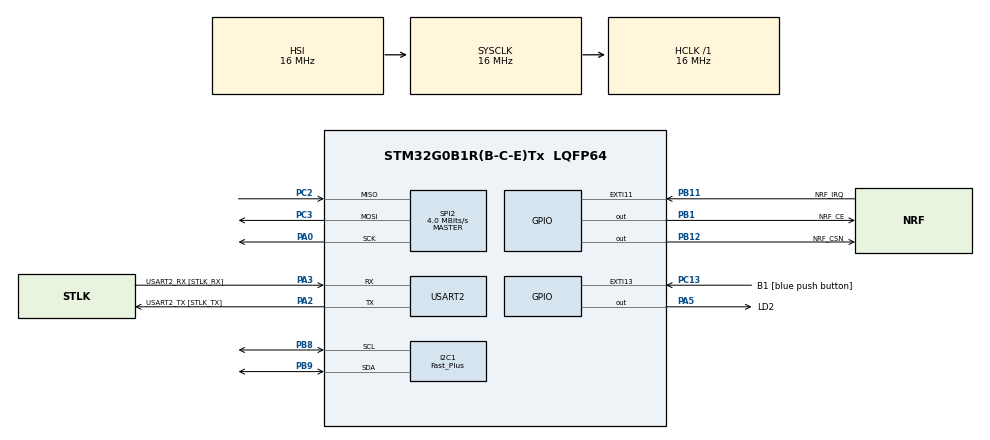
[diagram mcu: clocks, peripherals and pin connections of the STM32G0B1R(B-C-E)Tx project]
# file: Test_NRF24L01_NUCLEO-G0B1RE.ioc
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I2C1.I2C_Speed_Mode=I2C_Fast_Plus
I2C1.Timing=0x00200105
Mcu.Family=STM32G0
Mcu.Name=STM32G0B1R(B-C-E)Tx
Mcu.Package=LQFP64
PA0.Mode=Full_Duplex_Master
PA0.Signal=SPI2_SCK
PA13.GPIO_Label=TMS
PA13.Mode=Serial_Wire
PA13.Signal=SYS_SWDIO
PA14-BOOT0.GPIO_Label=TCK
PA14-BOOT0.Mode=Serial_Wire
PA14-BOOT0.Signal=SYS_SWCLK
PA2.GPIO_Label=USART2_TX [STLK_TX]
PA2.Mode=Asynchronous
PA2.Signal=USART2_TX
PA3.GPIO_Label=USART2_RX [STLK_RX]
PA3.Mode=Asynchronous
PA3.Signal=USART2_RX
PA5.GPIO_Label=LD2
PA5.GPIO_Speed=GPIO_SPEED_FREQ_HIGH
PA5.Signal=GPIO_Output
PB1.GPIO_Label=NRF_CE
PB1.Signal=GPIO_Output
PB11.GPIO_Label=NRF_IRQ
PB11.Signal=GPXTI11
PB12.GPIO_Label=NRF_CSN
PB12.Signal=GPIO_Output
PB8.Mode=I2C
PB8.Signal=I2C1_SCL
PB9.Mode=I2C
PB9.Signal=I2C1_SDA
PC13.GPIO_Label=B1 [blue push button]
PC13.Signal=GPXTI13
PC14-OSC32_IN\ (PC14).Mode=LSE-External-Oscillator
PC14-OSC32_IN\ (PC14).Signal=RCC_OSC32_IN
PC15-OSC32_OUT\ (PC15).Mode=LSE-External-Oscillator
PC15-OSC32_OUT\ (PC15).Signal=RCC_OSC32_OUT
PC2.Mode=Full_Duplex_Master
PC2.Signal=SPI2_MISO
PC3.Mode=Full_Duplex_Master
PC3.Signal=SPI2_MOSI
PF0-OSC_IN\ (PF0).GPIO_Label=MCO
PF0-OSC_IN\ (PF0).Mode=HSE-External-Clock-Source
PF0-OSC_IN\ (PF0).Signal=RCC_OSC_IN
ProjectManager.HeapSize=0x200
ProjectManager.StackSize=0x400
ProjectManager.TargetToolchain=STM32CubeIDE
RCC.AHBFreq_Value=16000000
RCC.CortexFreq_Value=16000000
RCC.EXTERNAL_CLOCK_VALUE=12288000
RCC.HCLKFreq_Value=16000000
RCC.HSE_VALUE=8000000
RCC.HSI48_VALUE=48000000
RCC.HSI_VALUE=16000000
RCC.SYSCLKFreq_VALUE=16000000
RCC.USBFreq_Value=48000000
RCC.VCOOutputFreq_Value=128000000
SPI2.BaudRatePrescaler=SPI_BAUDRATEPRESCALER_4
SPI2.CalculateBaudRate=4.0 MBits/s
SPI2.DataSize=SPI_DATASIZE_8BIT
SPI2.Direction=SPI_DIRECTION_2LINES
SPI2.Mode=SPI_MODE_MASTER
SPI2.NSSPMode=SPI_NSS_PULSE_DISABLE
SPI2.VirtualType=VM_MASTER
USART2.VirtualMode-Asynchronous=VM_ASYNC
VP_SYS_VS_DBSignals.Mode=DisableDeadBatterySignals
board=NUCLEO-G0B1RE

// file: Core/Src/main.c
/* USER CODE BEGIN Header */
/**
  ******************************************************************************
  * @file           : main.c
  * @brief          : Main program body
  ******************************************************************************
  * @attention
  *
  * Copyright (c) 2025 STMicroelectronics.
  * All rights reserved.
  *
  * This software is licensed under terms that can be found in the LICENSE file
  * in the root directory of this software component.
  * If no LICENSE file comes with this software, it is provided AS-IS.
  *
  ******************************************************************************
  */
/* USER CODE END Header */
#include "main.h"

/* USER CODE BEGIN Includes */
#include "radio.h"
#include "nrf24.h"
#include "ssd1306.h"
#include "fonts.h"
#include "test_screen.h"

/* USER CODE END Includes */

I2C_HandleTypeDef hi2c1;

SPI_HandleTypeDef hspi2;

UART_HandleTypeDef huart2;

void SystemClock_Config(void);
static void MX_GPIO_Init(void);
static void MX_USART2_UART_Init(void);
static void MX_SPI2_Init(void);
static void MX_I2C1_Init(void);

int main(void)
{

  /* MCU Configuration--------------------------------------------------------*/

  /* Reset of all peripherals, Initializes the Flash interface and the Systick. */
  HAL_Init();

  /* Configure the system clock */
  SystemClock_Config();

  /* Initialize all configured peripherals */
  MX_GPIO_Init();
  MX_USART2_UART_Init();
  MX_SPI2_Init();
  MX_I2C1_Init();
  /* USER CODE BEGIN 2 */

  // runTestScreen();
  runRadio();
  // runTestScreen();
  /* USER CODE END 2 */

  /* Infinite loop */
  while (1)
  {

  }
}

void SystemClock_Config(void)
{
  RCC_OscInitTypeDef RCC_OscInitStruct = {0};
  RCC_ClkInitTypeDef RCC_ClkInitStruct = {0};

  /** Configure the main internal regulator output voltage
  */
  HAL_PWREx_ControlVoltageScaling(PWR_REGULATOR_VOLTAGE_SCALE1);

  /** Initializes the RCC Oscillators according to the specified parameters
  * in the RCC_OscInitTypeDef structure.
  */
  RCC_OscInitStruct.OscillatorType = RCC_OSCILLATORTYPE_HSI;
  RCC_OscInitStruct.HSIState = RCC_HSI_ON;
  RCC_OscInitStruct.HSIDiv = RCC_HSI_DIV1;
  RCC_OscInitStruct.HSICalibrationValue = RCC_HSICALIBRATION_DEFAULT;
  RCC_OscInitStruct.PLL.PLLState = RCC_PLL_NONE;
  if (HAL_RCC_OscConfig(&RCC_OscInitStruct) != HAL_OK)
  {
    Error_Handler();
  }

  /** Initializes the CPU, AHB and APB buses clocks
  */
  RCC_ClkInitStruct.ClockType = RCC_CLOCKTYPE_HCLK|RCC_CLOCKTYPE_SYSCLK
                              |RCC_CLOCKTYPE_PCLK1;
  RCC_ClkInitStruct.SYSCLKSource = RCC_SYSCLKSOURCE_HSI;
  RCC_ClkInitStruct.AHBCLKDivider = RCC_SYSCLK_DIV1;
  RCC_ClkInitStruct.APB1CLKDivider = RCC_HCLK_DIV1;

  if (HAL_RCC_ClockConfig(&RCC_ClkInitStruct, FLASH_LATENCY_0) != HAL_OK)
  {
    Error_Handler();
  }
}

static void MX_I2C1_Init(void)
{

  hi2c1.Instance = I2C1;
  hi2c1.Init.Timing = 0x00200105;
  hi2c1.Init.OwnAddress1 = 0;
  hi2c1.Init.AddressingMode = I2C_ADDRESSINGMODE_7BIT;
  hi2c1.Init.DualAddressMode = I2C_DUALADDRESS_DISABLE;
  hi2c1.Init.OwnAddress2 = 0;
  hi2c1.Init.OwnAddress2Masks = I2C_OA2_NOMASK;
  hi2c1.Init.GeneralCallMode = I2C_GENERALCALL_DISABLE;
  hi2c1.Init.NoStretchMode = I2C_NOSTRETCH_DISABLE;
  if (HAL_I2C_Init(&hi2c1) != HAL_OK)
  {
    Error_Handler();
  }

  /** Configure Analogue filter
  */
  if (HAL_I2CEx_ConfigAnalogFilter(&hi2c1, I2C_ANALOGFILTER_ENABLE) != HAL_OK)
  {
    Error_Handler();
  }

  /** Configure Digital filter
  */
  if (HAL_I2CEx_ConfigDigitalFilter(&hi2c1, 0) != HAL_OK)
  {
    Error_Handler();
  }

  /** I2C Fast mode Plus enable
  */
  HAL_I2CEx_EnableFastModePlus(I2C_FASTMODEPLUS_I2C1);

}

static void MX_SPI2_Init(void)
{

  /* SPI2 parameter configuration*/
  hspi2.Instance = SPI2;
  hspi2.Init.Mode = SPI_MODE_MASTER;
  hspi2.Init.Direction = SPI_DIRECTION_2LINES;
  hspi2.Init.DataSize = SPI_DATASIZE_8BIT;
  hspi2.Init.CLKPolarity = SPI_POLARITY_LOW;
  hspi2.Init.CLKPhase = SPI_PHASE_1EDGE;
  hspi2.Init.NSS = SPI_NSS_SOFT;
  hspi2.Init.BaudRatePrescaler = SPI_BAUDRATEPRESCALER_4;
  hspi2.Init.FirstBit = SPI_FIRSTBIT_MSB;
  hspi2.Init.TIMode = SPI_TIMODE_DISABLE;
  hspi2.Init.CRCCalculation = SPI_CRCCALCULATION_DISABLE;
  hspi2.Init.CRCPolynomial = 7;
  hspi2.Init.CRCLength = SPI_CRC_LENGTH_DATASIZE;
  hspi2.Init.NSSPMode = SPI_NSS_PULSE_DISABLE;
  if (HAL_SPI_Init(&hspi2) != HAL_OK)
  {
    Error_Handler();
  }

}

static void MX_USART2_UART_Init(void)
{

  huart2.Instance = USART2;
  huart2.Init.BaudRate = 115200;
  huart2.Init.WordLength = UART_WORDLENGTH_8B;
  huart2.Init.StopBits = UART_STOPBITS_1;
  huart2.Init.Parity = UART_PARITY_NONE;
  huart2.Init.Mode = UART_MODE_TX_RX;
  huart2.Init.HwFlowCtl = UART_HWCONTROL_NONE;
  huart2.Init.OverSampling = UART_OVERSAMPLING_16;
  huart2.Init.OneBitSampling = UART_ONE_BIT_SAMPLE_DISABLE;
  huart2.Init.ClockPrescaler = UART_PRESCALER_DIV1;
  huart2.AdvancedInit.AdvFeatureInit = UART_ADVFEATURE_NO_INIT;
  if (HAL_UART_Init(&huart2) != HAL_OK)
  {
    Error_Handler();
  }
  if (HAL_UARTEx_SetTxFifoThreshold(&huart2, UART_TXFIFO_THRESHOLD_1_8) != HAL_OK)
  {
    Error_Handler();
  }
  if (HAL_UARTEx_SetRxFifoThreshold(&huart2, UART_RXFIFO_THRESHOLD_1_8) != HAL_OK)
  {
    Error_Handler();
  }
  if (HAL_UARTEx_DisableFifoMode(&huart2) != HAL_OK)
  {
    Error_Handler();
  }

}

static void MX_GPIO_Init(void)
{
  GPIO_InitTypeDef GPIO_InitStruct = {0};

  /* GPIO Ports Clock Enable */
  __HAL_RCC_GPIOC_CLK_ENABLE();
  __HAL_RCC_GPIOF_CLK_ENABLE();
  __HAL_RCC_GPIOA_CLK_ENABLE();
  __HAL_RCC_GPIOB_CLK_ENABLE();

  /*Configure GPIO pin Output Level */
  HAL_GPIO_WritePin(LD2_GPIO_Port, LD2_Pin, GPIO_PIN_RESET);

  /*Configure GPIO pin Output Level */
  HAL_GPIO_WritePin(GPIOB, NRF_CE_Pin|NRF_CSN_Pin, GPIO_PIN_RESET);

  /*Configure GPIO pin : B1_Pin */
  GPIO_InitStruct.Pin = B1_Pin;
  GPIO_InitStruct.Mode = GPIO_MODE_IT_RISING;
  GPIO_InitStruct.Pull = GPIO_NOPULL;
  HAL_GPIO_Init(B1_GPIO_Port, &GPIO_InitStruct);

  /*Configure GPIO pin : LD2_Pin */
  GPIO_InitStruct.Pin = LD2_Pin;
  GPIO_InitStruct.Mode = GPIO_MODE_OUTPUT_PP;
  GPIO_InitStruct.Pull = GPIO_NOPULL;
  GPIO_InitStruct.Speed = GPIO_SPEED_FREQ_HIGH;
  HAL_GPIO_Init(LD2_GPIO_Port, &GPIO_InitStruct);

  /*Configure GPIO pins : NRF_CE_Pin NRF_CSN_Pin */
  GPIO_InitStruct.Pin = NRF_CE_Pin|NRF_CSN_Pin;
  GPIO_InitStruct.Mode = GPIO_MODE_OUTPUT_PP;
  GPIO_InitStruct.Pull = GPIO_NOPULL;
  GPIO_InitStruct.Speed = GPIO_SPEED_FREQ_LOW;
  HAL_GPIO_Init(GPIOB, &GPIO_InitStruct);

  /*Configure GPIO pin : NRF_IRQ_Pin */
  GPIO_InitStruct.Pin = NRF_IRQ_Pin;
  GPIO_InitStruct.Mode = GPIO_MODE_IT_RISING;
  GPIO_InitStruct.Pull = GPIO_NOPULL;
  HAL_GPIO_Init(NRF_IRQ_GPIO_Port, &GPIO_InitStruct);

}

void Error_Handler(void)
{
  __disable_irq();
  while (1)
  {
  }
}
